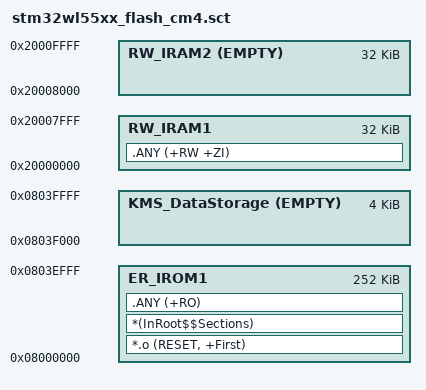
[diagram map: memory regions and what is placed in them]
; *************************************************************
; *** Scatter-Loading Description File generated by uVision ***
; *************************************************************

LR_IROM1 0x08000000 0x0003F000  {    ; load region size_region
  ; FLASH
  ER_IROM1 0x08000000 0x0003F000  {  ; load address = execution address
   *.o (RESET, +First)
   *(InRoot$$Sections)
   .ANY (+RO)
  }
  ; Non-backup SRAM1
  RW_IRAM1 0x20000000 0x00008000  {  ; RW data
   .ANY (+RW +ZI)
  }
  ; Backup SRAM2
  RW_IRAM2 0x20008000 EMPTY 0x00008000  {  ; to be modified accordingly to user project. Can be NoInit data for backup usage, RW, ZI region, etc...
  }
}

; KMS Data Storage (NVM) region
; KMS Data Storage need for 2 images : 2 kbytes * 2 ==> 2 kbytes
LR_KMS_DataStorage 0x0803F000 0x00001000 {
  KMS_DataStorage +0 EMPTY 0x00001000 {
  }
}
